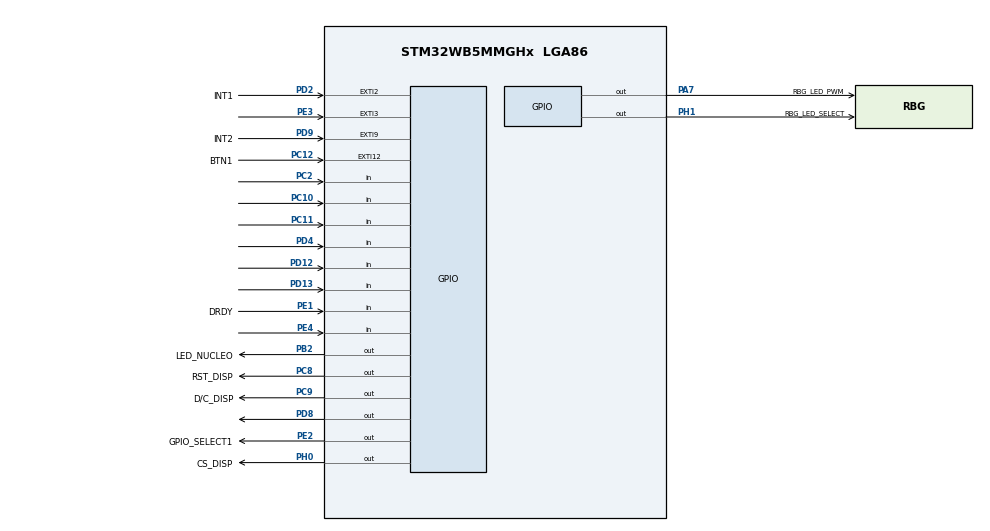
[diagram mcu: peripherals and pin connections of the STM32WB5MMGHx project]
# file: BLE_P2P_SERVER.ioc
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Mcu.Family=STM32WB
Mcu.Name=STM32WB5MMGHx
Mcu.Package=LGA86
NVIC.EXTI15_10_IRQn=true\:0\:0\:false\:false\:true\:true\:true\:true
NVIC.HSEM_IRQn=true\:0\:0\:false\:false\:true\:false\:true\:true
NVIC.IPCC_C1_RX_IRQn=true\:0\:0\:false\:false\:true\:true\:true\:true
NVIC.IPCC_C1_TX_IRQn=true\:0\:0\:false\:false\:true\:true\:true\:true
NVIC.PriorityGroup=NVIC_PRIORITYGROUP_4
PA0.Signal=ADCx_IN5
PA1.Signal=SPI1_SCK
PA10.Signal=I2C1_SDA
PA11.GPIO_Label=USB_N
PA11.Signal=USB_DM
PA12.GPIO_Label=USB_P
PA12.Signal=USB_DP
PA13.GPIO_Label=T_SWDIO
PA13.Mode=Serial_Wire
PA13.Signal=SYS_JTMS-SWDIO
PA14.GPIO_Label=T_SWCLK
PA14.Mode=Serial_Wire
PA14.Signal=SYS_JTCK-SWCLK
PA15.Signal=S_TIM2_CH1
PA2.Signal=ADCx_IN7
PA3.GPIO_Label=QSPI_BK_SCK
PA3.Signal=QUADSPI_CLK
PA4.Signal=SPI1_NSS
PA5.Signal=ADCx_IN10
PA6.Signal=LPUART1_CTS
PA7.GPIO_Label=RBG_LED_PWM
PA7.Signal=GPIO_Output
PA8.GPIO_Label=SAI1_CK2
PA8.Signal=SAI1_CK2
PA9.GPIO_Label=SAI1_D2
PA9.Signal=SAI1_D2
PB10.Signal=S_TIM2_CH3
PB11.GPIO_Label=I2C3_SDA
PB11.Signal=I2C3_SDA
PB12.Signal=LPUART1_RTS
PB13.GPIO_Label=I2C3_SCL
PB13.Signal=I2C3_SCL
PB14.Signal=SPI2_MISO
PB15.Signal=SPI2_MOSI
PB2.GPIO_Label=LED_NUCLEO
PB2.Signal=GPIO_Output
PB3.GPIO_Label=T_SWO
PB3.Signal=SYS_JTDO-SWO
PB4.Signal=SPI1_MISO
PB5.GPIO_Label=LPUART1_TX_MCU
PB5.Signal=LPUART1_TX
PB6.GPIO_Label=VCP_TX
PB6.Signal=USART1_TX
PB7.GPIO_Label=VCP_RX
PB7.Signal=USART1_RX
PB8.Signal=I2C1_SCL
PB9.GPIO_Label=QSPI_BK_IO0
PB9.Signal=QUADSPI_BK1_IO0
PC0.GPIO_Label=LPUART1_RX_MCU
PC0.Signal=LPUART1_RX
PC1.Signal=ADCx_IN2
PC10.Signal=GPIO_Input
PC11.Signal=GPIO_Input
PC12.GPIO_Label=BTN1
PC12.GPIO_ModeDefaultEXTI=GPIO_MODE_IT_FALLING
PC12.GPIO_PuPd=GPIO_PULLUP
PC12.Signal=GPXTI12
PC13.GPIO_Label=User-B2
PC13.Signal=SYS_WKUP2
PC2.Signal=GPIO_Input
PC3.Signal=ADCx_IN4
PC4.Signal=ADCx_IN13
PC5.Signal=ADCx_IN14
PC6.GPIO_Label=TSC_G4_IO1
PC6.Signal=TSC_G4_IO1
PC7.GPIO_Label=TSC_G4_IO2
PC7.Signal=TSC_G4_IO2
PC8.GPIO_Label=RST_DISP
PC8.Signal=GPIO_Output
PC9.GPIO_Label=D/C_DISP
PC9.Signal=GPIO_Output
PD0.Signal=SPI2_NSS
PD1.Signal=SPI2_SCK
PD10.GPIO_Label=TSC_G6_IO1
PD10.Signal=TSC_G6_IO1
PD11.GPIO_Label=TSC_G6_IO2
PD11.Signal=TSC_G6_IO2
PD12.Signal=GPIO_Input
PD13.Signal=GPIO_Input
PD14.Signal=S_TIM1_CH1
PD15.Signal=S_TIM1_CH2
PD2.GPIO_Label=INT1
PD2.Signal=GPXTI2
PD3.GPIO_Label=QSPI_BK_NCS
PD3.Signal=QUADSPI_BK1_NCS
PD4.Signal=GPIO_Input
PD5.GPIO_Label=QSPI_BK_IO1
PD5.Signal=QUADSPI_BK1_IO1
PD6.GPIO_Label=QSPI_BK_IO2
PD6.Signal=QUADSPI_BK1_IO2
PD8.Signal=GPIO_Output
PD9.GPIO_Label=INT2
PD9.Signal=GPXTI9
PE0.Signal=S_TIM16_CH1
PE1.GPIO_Label=DRDY
PE1.Signal=GPIO_Input
PE2.GPIO_Label=GPIO_SELECT1
PE2.Signal=GPIO_Output
PE3.Signal=GPXTI3
PE4.Signal=GPIO_Input
PH0.GPIO_Label=CS_DISP
PH0.Signal=GPIO_Output
PH1.GPIO_Label=RBG_LED_SELECT
PH1.Signal=GPIO_Output
ProjectManager.HeapSize=0x200
ProjectManager.StackSize=0x400
ProjectManager.TargetToolchain=STM32CubeIDE
RCC.ADCFreq_Value=128000000
RCC.AHBFreq_Value=32000000
RCC.APB1Freq_Value=32000000
RCC.APB1TimFreq_Value=32000000
RCC.APB2Freq_Value=32000000
RCC.APB2TimFreq_Value=32000000
RCC.APB3Freq_Value=16000000
RCC.CortexFreq_Value=32000000
RCC.HCLKFreq_Value=32000000
RCC.HSE_VALUE=32000000
RCC.HSI48_VALUE=48000000
RCC.HSI_VALUE=16000000
RCC.MSIClockRange=RCC_MSIRANGE_10
RCC.RFWKPClockSelection=RCC_RFWKPCLKSOURCE_LSE
RCC.RTCClockSelection=RCC_RTCCLKSOURCE_LSE
RCC.SYSCLKFreq_VALUE=32000000
RCC.USBFreq_Value=128000000
RCC.VCOOutputFreq_Value=256000000
SH.ADCx_IN10.0=ADC1_IN10
SH.ADCx_IN13.0=ADC1_IN13
SH.ADCx_IN14.0=ADC1_IN14
SH.ADCx_IN2.0=ADC1_IN2
SH.ADCx_IN4.0=ADC1_IN4
SH.ADCx_IN5.0=ADC1_IN5
SH.ADCx_IN7.0=ADC1_IN7
SH.S_TIM16_CH1.0=TIM16_CH1
SH.S_TIM1_CH1.0=TIM1_CH1
SH.S_TIM1_CH2.0=TIM1_CH2
SH.S_TIM2_CH1.0=TIM2_CH1
SH.S_TIM2_CH3.0=TIM2_CH3
STM32_WPAN.AD_TYPE_COMPLETE_LOCAL_NAME=STM32WB5MM-DK
STM32_WPAN.AD_TYPE_COMPLETE_LOCAL_NAME_LENGTH=14
STM32_WPAN.AD_TYPE_MANUFACTURER_DATA_1=13
STM32_WPAN.AD_TYPE_MANUFACTURER_DATA_COMMENT_1=BLE_OTA
STM32_WPAN.CFG_LSCLK_LSE=0
STM32_WPAN.CUSTOM_P2P_SERVER=Disabled
STM32_WPAN.CUSTOM_TEMPLATE=Enabled
STM32_WPAN.INCLUDE_AD_TYPE_COMPLETE_LOCAL_NAME=1
STM32_WPAN.INCLUDE_AD_TYPE_LE_ROLE=0
STM32_WPAN.INCLUDE_AD_TYPE_MANUFACTURER_SPECIFIC_DATA=1
STM32_WPAN.NUMBER_OF_SERVICES=1
STM32_WPAN.SERVICE1_CHAR1_GATT_NOTIFY_READ_REQ_AND_WAIT_FOR_APPL_RESP=\ 
STM32_WPAN.SERVICE1_CHAR1_GATT_NOTIFY_WRITE_REQ_AND_WAIT_FOR_APPL_RESP=\ 
STM32_WPAN.SERVICE1_CHAR1_LENGTH_CHARACTERISTIC=CHAR_VALUE_LEN_VARIABLE
STM32_WPAN.SERVICE1_CHAR1_LONG_NAME=LED_CONTROL_CHAR
STM32_WPAN.SERVICE1_CHAR1_PROP_READ=CHAR_PROP_READ
STM32_WPAN.SERVICE1_CHAR1_PROP_WRITE_WITHOUT_RESP=CHAR_PROP_WRITE_WITHOUT_RESP
STM32_WPAN.SERVICE1_CHAR1_SHORT_NAME=LED_CTRL_CHAR
STM32_WPAN.SERVICE1_CHAR1_UUID=FE 41
STM32_WPAN.SERVICE1_CHAR1_VALUE_LENGTH=2
STM32_WPAN.SERVICE1_CHAR2_GATT_NOTIFY_READ_REQ_AND_WAIT_FOR_APPL_RESP=\ 
STM32_WPAN.SERVICE1_CHAR2_GATT_NOTIFY_WRITE_REQ_AND_WAIT_FOR_APPL_RESP=\ 
STM32_WPAN.SERVICE1_CHAR2_LENGTH_CHARACTERISTIC=CHAR_VALUE_LEN_VARIABLE
STM32_WPAN.SERVICE1_CHAR2_LONG_NAME=NOTIFY_PUSH_BTN_CHAR
STM32_WPAN.SERVICE1_CHAR2_PROP_NOTIFY=CHAR_PROP_NOTIFY
STM32_WPAN.SERVICE1_CHAR2_SHORT_NAME=NOTIFY_PUSH_BTN_C
STM32_WPAN.SERVICE1_CHAR2_UUID=FE 42
STM32_WPAN.SERVICE1_CHAR2_VALUE_LENGTH=2
STM32_WPAN.SERVICE1_LONG_NAME=P2P_SERVICE
STM32_WPAN.SERVICE1_NUMBER_OF_CHARACTERISTICS=2
STM32_WPAN.SERVICE1_SHORT_NAME=P2P_SERVICE
STM32_WPAN.SERVICE1_UUID=FE 40
TIM17.Prescaler=0
VP_HSEM_VS_HSEM.Mode=HSEM_Activate
VP_IPCC_VS_IPCC.Mode=IPCC_Activate
VP_MEMORYMAP_VS_MEMORYMAP.Mode=CurAppReg
VP_RCC_V_OSC32_IN.Mode=LSE-External-Clock-Source
VP_RCC_V_OSC_IN.Mode=HSE-External-Clock-Source
VP_RF_VS_RF.Mode=RF_Activate
VP_RTC_VS_RTC_Activate.Mode=RTC_Enabled
VP_RTC_VS_RTC_WakeUp_intern.Mode=WakeUp
VP_SEQUENCER_VS_SEQUENCER.Mode=SEQUENCER_Enabled
VP_STM32_WPAN_VS_BLE_HOST.Mode=STM32_WPAN_Enabled
VP_TIM17_VS_ClockSourceINT.Mode=Enable_Timer
VP_TINY_LPM_VS_TINY_LPM.Mode=TINY_LPM_Enabled
board=STM32WB5MM-DK

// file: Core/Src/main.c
/* USER CODE BEGIN Header */
/**
 ******************************************************************************
 * @file           : main.c
 * @brief          : Main program body
 ******************************************************************************
 * @attention
 *
 * Copyright (c) 2026 STMicroelectronics.
 * All rights reserved.
 *
 * This software is licensed under terms that can be found in the LICENSE file
 * in the root directory of this software component.
 * If no LICENSE file comes with this software, it is provided AS-IS.
 *
 ******************************************************************************
 */
/* USER CODE END Header */
#include "main.h"

/* USER CODE BEGIN Includes */
#include "tlc59731.h"
/* USER CODE END Includes */

IPCC_HandleTypeDef hipcc;

RTC_HandleTypeDef hrtc;

TIM_HandleTypeDef htim17;

void SystemClock_Config(void);
void PeriphCommonClock_Config(void);
static void MX_GPIO_Init(void);
static void MX_IPCC_Init(void);
static void MX_RTC_Init(void);
static void MX_TIM17_Init(void);
static void MX_RF_Init(void);

int main(void)
{

	/* MCU Configuration--------------------------------------------------------*/

	/* Reset of all peripherals, Initializes the Flash interface and the Systick. */
	HAL_Init();
	/* Config code for STM32_WPAN (HSE Tuning must be done before system clock configuration) */
	MX_APPE_Config();

	/* Configure the system clock */
	SystemClock_Config();

	/* Configure the peripherals common clocks */
	PeriphCommonClock_Config();

	/* IPCC initialisation */
	MX_IPCC_Init();

	/* Initialize all configured peripherals */
	MX_GPIO_Init();
	MX_RTC_Init();
	MX_TIM17_Init();
	MX_RF_Init();
	/* USER CODE BEGIN 2 */
	TLC59731_Init(RBG_LED_PWM_GPIO_Port, RBG_LED_PWM_Pin, RBG_LED_SELECT_GPIO_Port, RBG_LED_SELECT_Pin, &htim17);
	TLC59731_SetRGB(0x00, 0x10, 0x00);
//	int delay = 500;
	/* USER CODE END 2 */

	/* Init code for STM32_WPAN */
	MX_APPE_Init();

	/* Infinite loop */
	/* USER CODE BEGIN WHILE */
	while (1)
	{
//		HAL_Delay(delay);
//		RGB_LED_Off();
//		HAL_Delay(delay);
//		RGB_LED_On();
		/* USER CODE END WHILE */
		MX_APPE_Process();

	}
}

void SystemClock_Config(void)
{
	RCC_OscInitTypeDef RCC_OscInitStruct =
	{ 0 };
	RCC_ClkInitTypeDef RCC_ClkInitStruct =
	{ 0 };

	/** Configure LSE Drive Capability
	 */
	HAL_PWR_EnableBkUpAccess();
	__HAL_RCC_LSEDRIVE_CONFIG(RCC_LSEDRIVE_MEDIUMHIGH);

	/** Configure the main internal regulator output voltage
	 */
	__HAL_PWR_VOLTAGESCALING_CONFIG(PWR_REGULATOR_VOLTAGE_SCALE1);

	/** Initializes the RCC Oscillators according to the specified parameters
	 * in the RCC_OscInitTypeDef structure.
	 */
	RCC_OscInitStruct.OscillatorType = RCC_OSCILLATORTYPE_HSI | RCC_OSCILLATORTYPE_HSE | RCC_OSCILLATORTYPE_LSE
			| RCC_OSCILLATORTYPE_MSI;
	RCC_OscInitStruct.HSEState = RCC_HSE_ON;
	RCC_OscInitStruct.LSEState = RCC_LSE_ON;
	RCC_OscInitStruct.HSIState = RCC_HSI_ON;
	RCC_OscInitStruct.MSIState = RCC_MSI_ON;
	RCC_OscInitStruct.HSICalibrationValue = RCC_HSICALIBRATION_DEFAULT;
	RCC_OscInitStruct.MSICalibrationValue = RCC_MSICALIBRATION_DEFAULT;
	RCC_OscInitStruct.MSIClockRange = RCC_MSIRANGE_10;
	RCC_OscInitStruct.PLL.PLLState = RCC_PLL_NONE;
	if (HAL_RCC_OscConfig(&RCC_OscInitStruct) != HAL_OK)
	{
		Error_Handler();
	}

	/** Configure the SYSCLKSource, HCLK, PCLK1 and PCLK2 clocks dividers
	 */
	RCC_ClkInitStruct.ClockType = RCC_CLOCKTYPE_HCLK4 | RCC_CLOCKTYPE_HCLK2 | RCC_CLOCKTYPE_HCLK | RCC_CLOCKTYPE_SYSCLK
			| RCC_CLOCKTYPE_PCLK1 | RCC_CLOCKTYPE_PCLK2;
	RCC_ClkInitStruct.SYSCLKSource = RCC_SYSCLKSOURCE_MSI;
	RCC_ClkInitStruct.AHBCLKDivider = RCC_SYSCLK_DIV1;
	RCC_ClkInitStruct.APB1CLKDivider = RCC_HCLK_DIV1;
	RCC_ClkInitStruct.APB2CLKDivider = RCC_HCLK_DIV1;
	RCC_ClkInitStruct.AHBCLK2Divider = RCC_SYSCLK_DIV1;
	RCC_ClkInitStruct.AHBCLK4Divider = RCC_SYSCLK_DIV1;

	if (HAL_RCC_ClockConfig(&RCC_ClkInitStruct, FLASH_LATENCY_1) != HAL_OK)
	{
		Error_Handler();
	}
}

void PeriphCommonClock_Config(void)
{
	RCC_PeriphCLKInitTypeDef PeriphClkInitStruct =
	{ 0 };

	/** Initializes the peripherals clock
	 */
	PeriphClkInitStruct.PeriphClockSelection = RCC_PERIPHCLK_SMPS | RCC_PERIPHCLK_RFWAKEUP;
	PeriphClkInitStruct.RFWakeUpClockSelection = RCC_RFWKPCLKSOURCE_LSE;
	PeriphClkInitStruct.SmpsClockSelection = RCC_SMPSCLKSOURCE_HSI;
	PeriphClkInitStruct.SmpsDivSelection = RCC_SMPSCLKDIV_RANGE1;

	if (HAL_RCCEx_PeriphCLKConfig(&PeriphClkInitStruct) != HAL_OK)
	{
		Error_Handler();
	}
}

static void MX_IPCC_Init(void)
{

	hipcc.Instance = IPCC;
	if (HAL_IPCC_Init(&hipcc) != HAL_OK)
	{
		Error_Handler();
	}

}

static void MX_RF_Init(void)
{

}

static void MX_RTC_Init(void)
{

	/** Initialize RTC Only
	 */
	hrtc.Instance = RTC;
	hrtc.Init.HourFormat = RTC_HOURFORMAT_24;
	hrtc.Init.AsynchPrediv = CFG_RTC_ASYNCH_PRESCALER;
	hrtc.Init.SynchPrediv = CFG_RTC_SYNCH_PRESCALER;
	hrtc.Init.OutPut = RTC_OUTPUT_DISABLE;
	hrtc.Init.OutPutPolarity = RTC_OUTPUT_POLARITY_HIGH;
	hrtc.Init.OutPutType = RTC_OUTPUT_TYPE_OPENDRAIN;
	hrtc.Init.OutPutRemap = RTC_OUTPUT_REMAP_NONE;
	if (HAL_RTC_Init(&hrtc) != HAL_OK)
	{
		Error_Handler();
	}

	/** Enable the WakeUp
	 */
	if (HAL_RTCEx_SetWakeUpTimer(&hrtc, 0, RTC_WAKEUPCLOCK_RTCCLK_DIV16) != HAL_OK)
	{
		Error_Handler();
	}

}

static void MX_TIM17_Init(void)
{

	htim17.Instance = TIM17;
	htim17.Init.Prescaler = 0;
	htim17.Init.CounterMode = TIM_COUNTERMODE_UP;
	htim17.Init.Period = 65535;
	htim17.Init.ClockDivision = TIM_CLOCKDIVISION_DIV1;
	htim17.Init.RepetitionCounter = 0;
	htim17.Init.AutoReloadPreload = TIM_AUTORELOAD_PRELOAD_DISABLE;
	if (HAL_TIM_Base_Init(&htim17) != HAL_OK)
	{
		Error_Handler();
	}

}

static void MX_GPIO_Init(void)
{
	GPIO_InitTypeDef GPIO_InitStruct =
	{ 0 };

	/* GPIO Ports Clock Enable */
	__HAL_RCC_GPIOA_CLK_ENABLE();
	__HAL_RCC_GPIOC_CLK_ENABLE();
	__HAL_RCC_GPIOB_CLK_ENABLE();
	__HAL_RCC_GPIOD_CLK_ENABLE();
	__HAL_RCC_GPIOE_CLK_ENABLE();
	__HAL_RCC_GPIOH_CLK_ENABLE();

	/*Configure GPIO pin Output Level */
	HAL_GPIO_WritePin(LED_NUCLEO_GPIO_Port, LED_NUCLEO_Pin, GPIO_PIN_RESET);

	/*Configure GPIO pin Output Level */
	HAL_GPIO_WritePin(RBG_LED_PWM_GPIO_Port, RBG_LED_PWM_Pin, GPIO_PIN_RESET);

	/*Configure GPIO pin Output Level */
	HAL_GPIO_WritePin(GPIOH, CS_DISP_Pin | RBG_LED_SELECT_Pin, GPIO_PIN_RESET);

	/*Configure GPIO pin Output Level */
	HAL_GPIO_WritePin(GPIOC, D_C_DISP_Pin | RST_DISP_Pin, GPIO_PIN_RESET);

	/*Configure GPIO pin Output Level */
	HAL_GPIO_WritePin(GPIOD, GPIO_PIN_8, GPIO_PIN_RESET);

	/*Configure GPIO pin Output Level */
	HAL_GPIO_WritePin(GPIO_SELECT1_GPIO_Port, GPIO_SELECT1_Pin, GPIO_PIN_RESET);

	/*Configure GPIO pins : PA2 PA0 PA5 */
	GPIO_InitStruct.Pin = GPIO_PIN_2 | GPIO_PIN_0 | GPIO_PIN_5;
	GPIO_InitStruct.Mode = GPIO_MODE_ANALOG;
	GPIO_InitStruct.Pull = GPIO_NOPULL;
	HAL_GPIO_Init(GPIOA, &GPIO_InitStruct);

	/*Configure GPIO pins : PA1 PA4 */
	GPIO_InitStruct.Pin = GPIO_PIN_1 | GPIO_PIN_4;
	GPIO_InitStruct.Mode = GPIO_MODE_AF_PP;
	GPIO_InitStruct.Pull = GPIO_NOPULL;
	GPIO_InitStruct.Speed = GPIO_SPEED_FREQ_LOW;
	GPIO_InitStruct.Alternate = GPIO_AF5_SPI1;
	HAL_GPIO_Init(GPIOA, &GPIO_InitStruct);

	/*Configure GPIO pins : PC3 PC1 PC5 PC4 */
	GPIO_InitStruct.Pin = GPIO_PIN_3 | GPIO_PIN_1 | GPIO_PIN_5 | GPIO_PIN_4;
	GPIO_InitStruct.Mode = GPIO_MODE_ANALOG;
	GPIO_InitStruct.Pull = GPIO_NOPULL;
	HAL_GPIO_Init(GPIOC, &GPIO_InitStruct);

	/*Configure GPIO pins : PC2 PC10 PC11 */
	GPIO_InitStruct.Pin = GPIO_PIN_2 | GPIO_PIN_10 | GPIO_PIN_11;
	GPIO_InitStruct.Mode = GPIO_MODE_INPUT;
	GPIO_InitStruct.Pull = GPIO_NOPULL;
	HAL_GPIO_Init(GPIOC, &GPIO_InitStruct);

	/*Configure GPIO pin : QSPI_BK_IO0_Pin */
	GPIO_InitStruct.Pin = QSPI_BK_IO0_Pin;
	GPIO_InitStruct.Mode = GPIO_MODE_AF_PP;
	GPIO_InitStruct.Pull = GPIO_NOPULL;
	GPIO_InitStruct.Speed = GPIO_SPEED_FREQ_LOW;
	GPIO_InitStruct.Alternate = GPIO_AF10_QUADSPI;
	HAL_GPIO_Init(QSPI_BK_IO0_GPIO_Port, &GPIO_InitStruct);

	/*Configure GPIO pin : LPUART1_RX_MCU_Pin */
	GPIO_InitStruct.Pin = LPUART1_RX_MCU_Pin;
	GPIO_InitStruct.Mode = GPIO_MODE_AF_PP;
	GPIO_InitStruct.Pull = GPIO_NOPULL;
	GPIO_InitStruct.Speed = GPIO_SPEED_FREQ_LOW;
	GPIO_InitStruct.Alternate = GPIO_AF8_LPUART1;
	HAL_GPIO_Init(LPUART1_RX_MCU_GPIO_Port, &GPIO_InitStruct);

	/*Configure GPIO pin : PB8 */
	GPIO_InitStruct.Pin = GPIO_PIN_8;
	GPIO_InitStruct.Mode = GPIO_MODE_AF_OD;
	GPIO_InitStruct.Pull = GPIO_NOPULL;
	GPIO_InitStruct.Speed = GPIO_SPEED_FREQ_LOW;
	GPIO_InitStruct.Alternate = GPIO_AF4_I2C1;
	HAL_GPIO_Init(GPIOB, &GPIO_InitStruct);

	/*Configure GPIO pins : VCP_RX_Pin VCP_TX_Pin */
	GPIO_InitStruct.Pin = VCP_RX_Pin | VCP_TX_Pin;
	GPIO_InitStruct.Mode = GPIO_MODE_AF_PP;
	GPIO_InitStruct.Pull = GPIO_NOPULL;
	GPIO_InitStruct.Speed = GPIO_SPEED_FREQ_LOW;
	GPIO_InitStruct.Alternate = GPIO_AF7_USART1;
	HAL_GPIO_Init(GPIOB, &GPIO_InitStruct);

	/*Configure GPIO pins : LPUART1_TX_MCU_Pin PB12 */
	GPIO_InitStruct.Pin = LPUART1_TX_MCU_Pin | GPIO_PIN_12;
	GPIO_InitStruct.Mode = GPIO_MODE_AF_PP;
	GPIO_InitStruct.Pull = GPIO_NOPULL;
	GPIO_InitStruct.Speed = GPIO_SPEED_FREQ_LOW;
	GPIO_InitStruct.Alternate = GPIO_AF8_LPUART1;
	HAL_GPIO_Init(GPIOB, &GPIO_InitStruct);

	/*Configure GPIO pin : PB4 */
	GPIO_InitStruct.Pin = GPIO_PIN_4;
	GPIO_InitStruct.Mode = GPIO_MODE_AF_PP;
	GPIO_InitStruct.Pull = GPIO_NOPULL;
	GPIO_InitStruct.Speed = GPIO_SPEED_FREQ_LOW;
	GPIO_InitStruct.Alternate = GPIO_AF5_SPI1;
	HAL_GPIO_Init(GPIOB, &GPIO_InitStruct);

	/*Configure GPIO pin : BTN1_Pin */
	GPIO_InitStruct.Pin = BTN1_Pin;
	GPIO_InitStruct.Mode = GPIO_MODE_IT_FALLING;
	GPIO_InitStruct.Pull = GPIO_PULLUP;
	HAL_GPIO_Init(BTN1_GPIO_Port, &GPIO_InitStruct);

	/*Configure GPIO pin : PA15 */
	GPIO_InitStruct.Pin = GPIO_PIN_15;
	GPIO_InitStruct.Mode = GPIO_MODE_AF_PP;
	GPIO_InitStruct.Pull = GPIO_NOPULL;
	GPIO_InitStruct.Speed = GPIO_SPEED_FREQ_LOW;
	GPIO_InitStruct.Alternate = GPIO_AF1_TIM2;
	HAL_GPIO_Init(GPIOA, &GPIO_InitStruct);

	/*Configure GPIO pin : PA10 */
	GPIO_InitStruct.Pin = GPIO_PIN_10;
	GPIO_InitStruct.Mode = GPIO_MODE_AF_OD;
	GPIO_InitStruct.Pull = GPIO_NOPULL;
	GPIO_InitStruct.Speed = GPIO_SPEED_FREQ_LOW;
	GPIO_InitStruct.Alternate = GPIO_AF4_I2C1;
	HAL_GPIO_Init(GPIOA, &GPIO_InitStruct);

	/*Configure GPIO pins : USB_P_Pin USB_N_Pin */
	GPIO_InitStruct.Pin = USB_P_Pin | USB_N_Pin;
	GPIO_InitStruct.Mode = GPIO_MODE_AF_PP;
	GPIO_InitStruct.Pull = GPIO_NOPULL;
	GPIO_InitStruct.Speed = GPIO_SPEED_FREQ_LOW;
	GPIO_InitStruct.Alternate = GPIO_AF10_USB;
	HAL_GPIO_Init(GPIOA, &GPIO_InitStruct);

	/*Configure GPIO pins : PD0 PD1 */
	GPIO_InitStruct.Pin = GPIO_PIN_0 | GPIO_PIN_1;
	GPIO_InitStruct.Mode = GPIO_MODE_AF_PP;
	GPIO_InitStruct.Pull = GPIO_NOPULL;
	GPIO_InitStruct.Speed = GPIO_SPEED_FREQ_LOW;
	GPIO_InitStruct.Alternate = GPIO_AF5_SPI2;
	HAL_GPIO_Init(GPIOD, &GPIO_InitStruct);

	/*Configure GPIO pins : I2C3_SCL_Pin I2C3_SDA_Pin */
	GPIO_InitStruct.Pin = I2C3_SCL_Pin | I2C3_SDA_Pin;
	GPIO_InitStruct.Mode = GPIO_MODE_AF_OD;
	GPIO_InitStruct.Pull = GPIO_NOPULL;
	GPIO_InitStruct.Speed = GPIO_SPEED_FREQ_LOW;
	GPIO_InitStruct.Alternate = GPIO_AF4_I2C3;
	HAL_GPIO_Init(GPIOB, &GPIO_InitStruct);

	/*Configure GPIO pins : TSC_G4_IO1_Pin TSC_G4_IO2_Pin */
	GPIO_InitStruct.Pin = TSC_G4_IO1_Pin | TSC_G4_IO2_Pin;
	GPIO_InitStruct.Mode = GPIO_MODE_AF_PP;
	GPIO_InitStruct.Pull = GPIO_NOPULL;
	GPIO_InitStruct.Speed = GPIO_SPEED_FREQ_LOW;
	GPIO_InitStruct.Alternate = GPIO_AF9_TSC;
	HAL_GPIO_Init(GPIOC, &GPIO_InitStruct);

	/*Configure GPIO pins : PB14 PB15 */
	GPIO_InitStruct.Pin = GPIO_PIN_14 | GPIO_PIN_15;
	GPIO_InitStruct.Mode = GPIO_MODE_AF_PP;
	GPIO_InitStruct.Pull = GPIO_NOPULL;
	GPIO_InitStruct.Speed = GPIO_SPEED_FREQ_LOW;
	GPIO_InitStruct.Alternate = GPIO_AF5_SPI2;
	HAL_GPIO_Init(GPIOB, &GPIO_InitStruct);

	/*Configure GPIO pins : PE4 DRDY_Pin */
	GPIO_InitStruct.Pin = GPIO_PIN_4 | DRDY_Pin;
	GPIO_InitStruct.Mode = GPIO_MODE_INPUT;
	GPIO_InitStruct.Pull = GPIO_NOPULL;
	HAL_GPIO_Init(GPIOE, &GPIO_InitStruct);

	/*Configure GPIO pin : PB10 */
	GPIO_InitStruct.Pin = GPIO_PIN_10;
	GPIO_InitStruct.Mode = GPIO_MODE_AF_PP;
	GPIO_InitStruct.Pull = GPIO_NOPULL;
	GPIO_InitStruct.Speed = GPIO_SPEED_FREQ_LOW;
	GPIO_InitStruct.Alternate = GPIO_AF1_TIM2;
	HAL_GPIO_Init(GPIOB, &GPIO_InitStruct);

	/*Configure GPIO pin : LED_NUCLEO_Pin */
	GPIO_InitStruct.Pin = LED_NUCLEO_Pin;
	GPIO_InitStruct.Mode = GPIO_MODE_OUTPUT_PP;
	GPIO_InitStruct.Pull = GPIO_NOPULL;
	GPIO_InitStruct.Speed = GPIO_SPEED_FREQ_LOW;
	HAL_GPIO_Init(LED_NUCLEO_GPIO_Port, &GPIO_InitStruct);

	/*Configure GPIO pins : SAI1_CK2_Pin SAI1_D2_Pin */
	GPIO_InitStruct.Pin = SAI1_CK2_Pin | SAI1_D2_Pin;
	GPIO_InitStruct.Mode = GPIO_MODE_AF_PP;
	GPIO_InitStruct.Pull = GPIO_NOPULL;
	GPIO_InitStruct.Speed = GPIO_SPEED_FREQ_LOW;
	GPIO_InitStruct.Alternate = GPIO_AF3_SAI1;
	HAL_GPIO_Init(GPIOA, &GPIO_InitStruct);

	/*Configure GPIO pin : RBG_LED_PWM_Pin */
	GPIO_InitStruct.Pin = RBG_LED_PWM_Pin;
	GPIO_InitStruct.Mode = GPIO_MODE_OUTPUT_PP;
	GPIO_InitStruct.Pull = GPIO_NOPULL;
	GPIO_InitStruct.Speed = GPIO_SPEED_FREQ_LOW;
	HAL_GPIO_Init(RBG_LED_PWM_GPIO_Port, &GPIO_InitStruct);

	/*Configure GPIO pin : PA6 */
	GPIO_InitStruct.Pin = GPIO_PIN_6;
	GPIO_InitStruct.Mode = GPIO_MODE_AF_PP;
	GPIO_InitStruct.Pull = GPIO_NOPULL;
	GPIO_InitStruct.Speed = GPIO_SPEED_FREQ_LOW;
	GPIO_InitStruct.Alternate = GPIO_AF8_LPUART1;
	HAL_GPIO_Init(GPIOA, &GPIO_InitStruct);

	/*Configure GPIO pin : QSPI_BK_SCK_Pin */
	GPIO_InitStruct.Pin = QSPI_BK_SCK_Pin;
	GPIO_InitStruct.Mode = GPIO_MODE_AF_PP;
	GPIO_InitStruct.Pull = GPIO_NOPULL;
	GPIO_InitStruct.Speed = GPIO_SPEED_FREQ_LOW;
	GPIO_InitStruct.Alternate = GPIO_AF10_QUADSPI;
	HAL_GPIO_Init(QSPI_BK_SCK_GPIO_Port, &GPIO_InitStruct);

	/*Configure GPIO pins : CS_DISP_Pin RBG_LED_SELECT_Pin */
	GPIO_InitStruct.Pin = CS_DISP_Pin | RBG_LED_SELECT_Pin;
	GPIO_InitStruct.Mode = GPIO_MODE_OUTPUT_PP;
	GPIO_InitStruct.Pull = GPIO_NOPULL;
	GPIO_InitStruct.Speed = GPIO_SPEED_FREQ_LOW;
	HAL_GPIO_Init(GPIOH, &GPIO_InitStruct);

	/*Configure GPIO pins : PD14 PD15 */
	GPIO_InitStruct.Pin = GPIO_PIN_14 | GPIO_PIN_15;
	GPIO_InitStruct.Mode = GPIO_MODE_AF_PP;
	GPIO_InitStruct.Pull = GPIO_NOPULL;
	GPIO_InitStruct.Speed = GPIO_SPEED_FREQ_LOW;
	GPIO_InitStruct.Alternate = GPIO_AF1_TIM1;
	HAL_GPIO_Init(GPIOD, &GPIO_InitStruct);

	/*Configure GPIO pins : PD13 PD12 PD4 */
	GPIO_InitStruct.Pin = GPIO_PIN_13 | GPIO_PIN_12 | GPIO_PIN_4;
	GPIO_InitStruct.Mode = GPIO_MODE_INPUT;
	GPIO_InitStruct.Pull = GPIO_NOPULL;
	HAL_GPIO_Init(GPIOD, &GPIO_InitStruct);

	/*Configure GPIO pins : INT1_Pin INT2_Pin */
	GPIO_InitStruct.Pin = INT1_Pin | INT2_Pin;
	GPIO_InitStruct.Mode = GPIO_MODE_IT_RISING;
	GPIO_InitStruct.Pull = GPIO_NOPULL;
	HAL_GPIO_Init(GPIOD, &GPIO_InitStruct);

	/*Configure GPIO pins : D_C_DISP_Pin RST_DISP_Pin */
	GPIO_InitStruct.Pin = D_C_DISP_Pin | RST_DISP_Pin;
	GPIO_InitStruct.Mode = GPIO_MODE_OUTPUT_PP;
	GPIO_InitStruct.Pull = GPIO_NOPULL;
	GPIO_InitStruct.Speed = GPIO_SPEED_FREQ_LOW;
	HAL_GPIO_Init(GPIOC, &GPIO_InitStruct);

	/*Configure GPIO pins : QSPI_BK_NCS_Pin QSPI_BK_IO1_Pin QSPI_BK_IO2_Pin */
	GPIO_InitStruct.Pin = QSPI_BK_NCS_Pin | QSPI_BK_IO1_Pin | QSPI_BK_IO2_Pin;
	GPIO_InitStruct.Mode = GPIO_MODE_AF_PP;
	GPIO_InitStruct.Pull = GPIO_NOPULL;
	GPIO_InitStruct.Speed = GPIO_SPEED_FREQ_LOW;
	GPIO_InitStruct.Alternate = GPIO_AF10_QUADSPI;
	HAL_GPIO_Init(GPIOD, &GPIO_InitStruct);

	/*Configure GPIO pin : PE3 */
	GPIO_InitStruct.Pin = GPIO_PIN_3;
	GPIO_InitStruct.Mode = GPIO_MODE_IT_RISING;
	GPIO_InitStruct.Pull = GPIO_NOPULL;
	HAL_GPIO_Init(GPIOE, &GPIO_InitStruct);

	/*Configure GPIO pin : PD8 */
	GPIO_InitStruct.Pin = GPIO_PIN_8;
	GPIO_InitStruct.Mode = GPIO_MODE_OUTPUT_PP;
	GPIO_InitStruct.Pull = GPIO_NOPULL;
	GPIO_InitStruct.Speed = GPIO_SPEED_FREQ_LOW;
	HAL_GPIO_Init(GPIOD, &GPIO_InitStruct);

	/*Configure GPIO pins : TSC_G6_IO1_Pin TSC_G6_IO2_Pin */
	GPIO_InitStruct.Pin = TSC_G6_IO1_Pin | TSC_G6_IO2_Pin;
	GPIO_InitStruct.Mode = GPIO_MODE_AF_PP;
	GPIO_InitStruct.Pull = GPIO_NOPULL;
	GPIO_InitStruct.Speed = GPIO_SPEED_FREQ_LOW;
	GPIO_InitStruct.Alternate = GPIO_AF9_TSC;
	HAL_GPIO_Init(GPIOD, &GPIO_InitStruct);

	/*Configure GPIO pin : GPIO_SELECT1_Pin */
	GPIO_InitStruct.Pin = GPIO_SELECT1_Pin;
	GPIO_InitStruct.Mode = GPIO_MODE_OUTPUT_PP;
	GPIO_InitStruct.Pull = GPIO_NOPULL;
	GPIO_InitStruct.Speed = GPIO_SPEED_FREQ_LOW;
	HAL_GPIO_Init(GPIO_SELECT1_GPIO_Port, &GPIO_InitStruct);

	/*Configure GPIO pin : PE0 */
	GPIO_InitStruct.Pin = GPIO_PIN_0;
	GPIO_InitStruct.Mode = GPIO_MODE_AF_PP;
	GPIO_InitStruct.Pull = GPIO_NOPULL;
	GPIO_InitStruct.Speed = GPIO_SPEED_FREQ_LOW;
	GPIO_InitStruct.Alternate = GPIO_AF14_TIM16;
	HAL_GPIO_Init(GPIOE, &GPIO_InitStruct);

	/* EXTI interrupt init*/
	HAL_NVIC_SetPriority(EXTI15_10_IRQn, 0, 0);
	HAL_NVIC_EnableIRQ(EXTI15_10_IRQn);

}

void Error_Handler(void)
{
	__disable_irq();
	while (1)
	{
	}
}
#ifdef USE_FULL_ASSERT
/**
  * @brief  Reports the name of the source file and the source line number
  *         where the assert_param error has occurred.
  * @param  file: pointer to the source file name
  * @param  line: assert_param error line source number
  * @retval None
  */
void assert_failed(uint8_t *file, uint32_t line)
{
  /* USER CODE BEGIN 6 */
  /* User can add his own implementation to report the file name and line
     number, ex: printf("Wrong parameters value: file %s on line %d\r\n", file,
     line) */
  /* USER CODE END 6 */
}
#endif /* USE_FULL_ASSERT */
